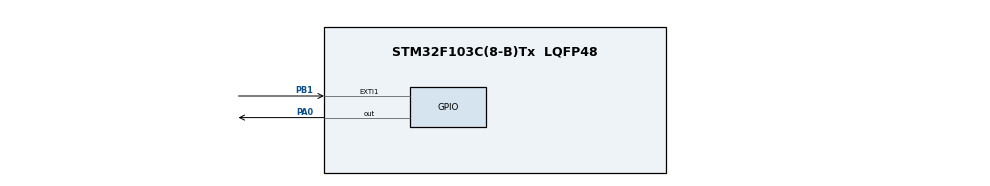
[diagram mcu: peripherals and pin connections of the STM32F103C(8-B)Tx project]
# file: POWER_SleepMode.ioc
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Mcu.Family=STM32F1
Mcu.Name=STM32F103C(8-B)Tx
Mcu.Package=LQFP48
NVIC.EXTI1_IRQn=true\:0\:0\:false\:false\:true\:true\:true
NVIC.PriorityGroup=NVIC_PRIORITYGROUP_4
PA0-WKUP.Signal=GPIO_Output
PA13.Mode=Serial_Wire
PA13.Signal=SYS_JTMS-SWDIO
PA14.Mode=Serial_Wire
PA14.Signal=SYS_JTCK-SWCLK
PB1.GPIO_ModeDefaultEXTI=GPIO_MODE_IT_FALLING
PB1.GPIO_PuPd=GPIO_PULLUP
PB1.Signal=GPXTI1
ProjectManager.HeapSize=0x200
ProjectManager.StackSize=0x400
ProjectManager.TargetToolchain=MDK-ARM V5
RCC.APB1Freq_Value=8000000
RCC.APB2Freq_Value=8000000
board=custom

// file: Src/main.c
/* USER CODE BEGIN Header */
/**
  ******************************************************************************
  * @file           : main.c
  * @brief          : Main program body
  ******************************************************************************
  * @attention
  *
  * <h2><center>&copy; Copyright (c) 2019 STMicroelectronics.
  * All rights reserved.</center></h2>
  *
  * This software component is licensed by ST under BSD 3-Clause license,
  * the "License"; You may not use this file except in compliance with the
  * License. You may obtain a copy of the License at:
  *                        opensource.org/licenses/BSD-3-Clause
  *
  ******************************************************************************
  */
	/* --COPYRIGHT--,
	 * Copyright (c) 2019, TAPIT Co., Ltd.
	 * https://tapit.vn
	 * **************************** POWER_SleepMode ******************************
	 *  Description: For MCU in Sleep mode, wake up when user press the Reset or
			EXTI button.
	 *  Version:    1.0
	 *  Author:     Hang Tran
	 *  Release:    May 27, 2019
	 *  Built with CubeMX Version 5.2.0 and Keil C Version 5.26.2
	 *****************************************************************************
	 */
/* USER CODE END Header */

#include "main.h"

void SystemClock_Config(void);
static void MX_GPIO_Init(void);

int main(void)
{

  /* MCU Configuration--------------------------------------------------------*/

  /* Reset of all peripherals, Initializes the Flash interface and the Systick. */
  HAL_Init();

  /* Configure the system clock */
  SystemClock_Config();

  /* Initialize all configured peripherals */
  MX_GPIO_Init();
  /* USER CODE BEGIN 2 */
	HAL_GPIO_WritePin(GPIOA, GPIO_PIN_0, GPIO_PIN_SET); // Led ON for 5s
	HAL_Delay(5000);

  /* USER CODE END 2 */

  /* Infinite loop */
  while (1)
  {

    /* USER CODE BEGIN 3 */
		HAL_SuspendTick(); // Suspend Tick increment to prevent wakeup by Systick interrupt
		HAL_GPIO_WritePin(GPIOA, GPIO_PIN_0, GPIO_PIN_RESET); // Led OFF to indicate that MCU enters SLEEP mode
		HAL_PWR_EnterSLEEPMode(PWR_MAINREGULATOR_ON, PWR_SLEEPENTRY_WFI); // Enter Sleep Mode
		HAL_ResumeTick(); // Resume Tick interrupt if disabled prior to SLEEP mode entry
		for(int i = 0; i < 6; i++) // Toggle Led for 6s to make sure MCU is exit from SLEEP mode
		{
			HAL_GPIO_TogglePin(GPIOA, GPIO_PIN_0);
			HAL_Delay(1000);
		}
  }
  /* USER CODE END 3 */
}

void SystemClock_Config(void)
{
  RCC_OscInitTypeDef RCC_OscInitStruct = {0};
  RCC_ClkInitTypeDef RCC_ClkInitStruct = {0};

  /** Initializes the CPU, AHB and APB busses clocks
  */
  RCC_OscInitStruct.OscillatorType = RCC_OSCILLATORTYPE_HSI;
  RCC_OscInitStruct.HSIState = RCC_HSI_ON;
  RCC_OscInitStruct.HSICalibrationValue = RCC_HSICALIBRATION_DEFAULT;
  RCC_OscInitStruct.PLL.PLLState = RCC_PLL_NONE;
  if (HAL_RCC_OscConfig(&RCC_OscInitStruct) != HAL_OK)
  {
    Error_Handler();
  }
  /** Initializes the CPU, AHB and APB busses clocks
  */
  RCC_ClkInitStruct.ClockType = RCC_CLOCKTYPE_HCLK|RCC_CLOCKTYPE_SYSCLK
                              |RCC_CLOCKTYPE_PCLK1|RCC_CLOCKTYPE_PCLK2;
  RCC_ClkInitStruct.SYSCLKSource = RCC_SYSCLKSOURCE_HSI;
  RCC_ClkInitStruct.AHBCLKDivider = RCC_SYSCLK_DIV1;
  RCC_ClkInitStruct.APB1CLKDivider = RCC_HCLK_DIV1;
  RCC_ClkInitStruct.APB2CLKDivider = RCC_HCLK_DIV1;

  if (HAL_RCC_ClockConfig(&RCC_ClkInitStruct, FLASH_LATENCY_0) != HAL_OK)
  {
    Error_Handler();
  }
}

static void MX_GPIO_Init(void)
{
  GPIO_InitTypeDef GPIO_InitStruct = {0};

  /* GPIO Ports Clock Enable */
  __HAL_RCC_GPIOA_CLK_ENABLE();
  __HAL_RCC_GPIOB_CLK_ENABLE();

  /*Configure GPIO pin Output Level */
  HAL_GPIO_WritePin(GPIOA, GPIO_PIN_0, GPIO_PIN_RESET);

  /*Configure GPIO pin : PA0 */
  GPIO_InitStruct.Pin = GPIO_PIN_0;
  GPIO_InitStruct.Mode = GPIO_MODE_OUTPUT_PP;
  GPIO_InitStruct.Pull = GPIO_NOPULL;
  GPIO_InitStruct.Speed = GPIO_SPEED_FREQ_LOW;
  HAL_GPIO_Init(GPIOA, &GPIO_InitStruct);

  /*Configure GPIO pin : PB1 */
  GPIO_InitStruct.Pin = GPIO_PIN_1;
  GPIO_InitStruct.Mode = GPIO_MODE_IT_FALLING;
  GPIO_InitStruct.Pull = GPIO_PULLUP;
  HAL_GPIO_Init(GPIOB, &GPIO_InitStruct);

  /* EXTI interrupt init*/
  HAL_NVIC_SetPriority(EXTI1_IRQn, 0, 0);
  HAL_NVIC_EnableIRQ(EXTI1_IRQn);

}

void Error_Handler(void)
{
}

/************************ (C) COPYRIGHT STMicroelectronics *****END OF FILE****/
